AUTOSAR XML (schema 00046)
package /ComponentTypes
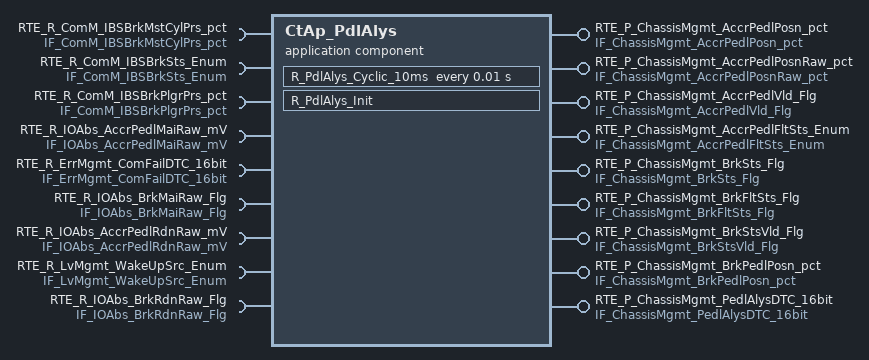
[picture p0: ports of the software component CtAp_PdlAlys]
  application sw component type CtAp_PdlAlys
    9 x provide port:
      RTE_P_ChassisMgmt_AccrPedlPosn_pct: nonqueued-sender-com-spec{data-element=tec_ChassisMgmt_AccrPedlPosn_pct, init-value=0}, provided-interface=IF_ChassisMgmt_AccrPedlPosn_pct
      RTE_P_ChassisMgmt_AccrPedlPosnRaw_pct: nonqueued-sender-com-spec{data-element=tec_ChassisMgmt_AccrPedlPosnRaw_pct, init-value=0}, provided-interface=IF_ChassisMgmt_AccrPedlPosnRaw_pct
      RTE_P_ChassisMgmt_AccrPedlVld_Flg: nonqueued-sender-com-spec{data-element=tec_ChassisMgmt_AccrPedlVld_Flg, init-value=0}, provided-interface=IF_ChassisMgmt_AccrPedlVld_Flg
      RTE_P_ChassisMgmt_AccrPedlFltSts_Enum: nonqueued-sender-com-spec{data-element=tec_ChassisMgmt_AccrPedlFltSts_Enum, init-value=0}, provided-interface=IF_ChassisMgmt_AccrPedlFltSts_Enum
      RTE_P_ChassisMgmt_BrkSts_Flg: nonqueued-sender-com-spec{data-element=tec_ChassisMgmt_BrkSts_Flg, init-value=0}, provided-interface=IF_ChassisMgmt_BrkSts_Flg
      RTE_P_ChassisMgmt_BrkFltSts_Flg: nonqueued-sender-com-spec{data-element=tec_ChassisMgmt_BrkFltSts_Flg, init-value=0}, provided-interface=IF_ChassisMgmt_BrkFltSts_Flg
      RTE_P_ChassisMgmt_BrkStsVld_Flg: nonqueued-sender-com-spec{data-element=tec_ChassisMgmt_BrkStsVld_Flg, init-value=0}, provided-interface=IF_ChassisMgmt_BrkStsVld_Flg
      RTE_P_ChassisMgmt_BrkPedlPosn_pct: nonqueued-sender-com-spec{data-element=tec_ChassisMgmt_BrkPedlPosn_pct, init-value=0}, provided-interface=IF_ChassisMgmt_BrkPedlPosn_pct
      RTE_P_ChassisMgmt_PedlAlysDTC_16bit: nonqueued-sender-com-spec{data-element=tec_ChassisMgmt_PedlAlysDTC_16bit, init-value=0}, provided-interface=IF_ChassisMgmt_PedlAlysDTC_16bit
    9 x require port:
      RTE_R_ComM_IBSBrkMstCylPrs_pct: nonqueued-receiver-com-spec{data-element=tec_ComM_IBSBrkMstCylPrs_pct, filter=data-filter-type=ALWAYS, init-value=0}, required-interface=IF_ComM_IBSBrkMstCylPrs_pct
      RTE_R_ComM_IBSBrkSts_Enum: nonqueued-receiver-com-spec{data-element=tec_ComM_IBSBrkSts_Enum, filter=data-filter-type=ALWAYS, init-value=0}, required-interface=IF_ComM_IBSBrkSts_Enum
      RTE_R_ComM_IBSBrkPlgrPrs_pct: nonqueued-receiver-com-spec{data-element=tec_ComM_IBSBrkPlgrPrs_pct, filter=data-filter-type=ALWAYS, init-value=0}, required-interface=IF_ComM_IBSBrkPlgrPrs_pct
      RTE_R_IOAbs_AccrPedlMaiRaw_mV: nonqueued-receiver-com-spec{data-element=tec_IOAbs_AccrPedlMaiRaw_mV, filter=data-filter-type=ALWAYS, init-value=0}, required-interface=IF_IOAbs_AccrPedlMaiRaw_mV
      RTE_R_ErrMgmt_ComFailDTC_16bit: nonqueued-receiver-com-spec{data-element=tec_ErrMgmt_ComFailDTC_16bit, filter=data-filter-type=ALWAYS, init-value=0}, required-interface=IF_ErrMgmt_ComFailDTC_16bit
      RTE_R_IOAbs_BrkMaiRaw_Flg: nonqueued-receiver-com-spec{data-element=tec_IOAbs_BrkMaiRaw_Flg, filter=data-filter-type=ALWAYS, init-value=0}, required-interface=IF_IOAbs_BrkMaiRaw_Flg
      RTE_R_IOAbs_AccrPedlRdnRaw_mV: nonqueued-receiver-com-spec{data-element=tec_IOAbs_AccrPedlRdnRaw_mV, filter=data-filter-type=ALWAYS, init-value=0}, required-interface=IF_IOAbs_AccrPedlRdnRaw_mV
      RTE_R_LvMgmt_WakeUpSrc_Enum: nonqueued-receiver-com-spec{data-element=tec_LvMgmt_WakeUpSrc_Enum, filter=data-filter-type=ALWAYS, init-value=0}, required-interface=IF_LvMgmt_WakeUpSrc_Enum
      RTE_R_IOAbs_BrkRdnRaw_Flg: nonqueued-receiver-com-spec{data-element=tec_IOAbs_BrkRdnRaw_Flg, filter=data-filter-type=ALWAYS, init-value=0}, required-interface=IF_IOAbs_BrkRdnRaw_Flg
    behavior CtAp_PdlAlys_InternalBehavior
      init event CtAp_PdlAlys_InitEvent: start-on-event=R_PdlAlys_Init
      timing event TMT_R_PdlAlys_Cyclic_10ms: start-on-event=R_PdlAlys_Cyclic_10ms, period=0.01
      runnable R_PdlAlys_Init
      runnable R_PdlAlys_Cyclic_10ms
        data-receive-point-by-arguments:
          9 x access:
            REC_RTE_R_ComM_IBSBrkMstCylPrs_pct_tec_ComM_IBSBrkMstCylPrs_pct: accessed-variable=RTE_R_ComM_IBSBrkMstCylPrs_pct.tec_ComM_IBSBrkMstCylPrs_pct
            REC_RTE_R_ComM_IBSBrkPlgrPrs_pct_tec_ComM_IBSBrkPlgrPrs_pct: accessed-variable=RTE_R_ComM_IBSBrkPlgrPrs_pct.tec_ComM_IBSBrkPlgrPrs_pct
            REC_RTE_R_ComM_IBSBrkSts_Enum_tec_ComM_IBSBrkSts_Enum: accessed-variable=RTE_R_ComM_IBSBrkSts_Enum.tec_ComM_IBSBrkSts_Enum
            REC_RTE_R_ErrMgmt_ComFailDTC_16bit_tec_ErrMgmt_ComFailDTC_16bit: accessed-variable=RTE_R_ErrMgmt_ComFailDTC_16bit.tec_ErrMgmt_ComFailDTC_16bit
            REC_RTE_R_IOAbs_AccrPedlMaiRaw_mV_tec_IOAbs_AccrPedlMaiRaw_mV: accessed-variable=RTE_R_IOAbs_AccrPedlMaiRaw_mV.tec_IOAbs_AccrPedlMaiRaw_mV
            REC_RTE_R_IOAbs_AccrPedlRdnRaw_mV_tec_IOAbs_AccrPedlRdnRaw_mV: accessed-variable=RTE_R_IOAbs_AccrPedlRdnRaw_mV.tec_IOAbs_AccrPedlRdnRaw_mV
            REC_RTE_R_IOAbs_BrkMaiRaw_Flg_tec_IOAbs_BrkMaiRaw_Flg: accessed-variable=RTE_R_IOAbs_BrkMaiRaw_Flg.tec_IOAbs_BrkMaiRaw_Flg
            REC_RTE_R_LvMgmt_WakeUpSrc_Enum_tec_LvMgmt_WakeUpSrc_Enum: accessed-variable=RTE_R_LvMgmt_WakeUpSrc_Enum.tec_LvMgmt_WakeUpSrc_Enum
            REC_RTE_R_IOAbs_BrkRdnRaw_Flg_tec_IOAbs_BrkRdnRaw_Flg: accessed-variable=RTE_R_IOAbs_BrkRdnRaw_Flg.tec_IOAbs_BrkRdnRaw_Flg
        data-send-points:
          9 x access:
            SEND_RTE_P_ChassisMgmt_AccrPedlFltSts_Enum_tec_ChassisMgmt_AccrPedlFltSts_Enum: accessed-variable=RTE_P_ChassisMgmt_AccrPedlFltSts_Enum.tec_ChassisMgmt_AccrPedlFltSts_Enum
            SEND_RTE_P_ChassisMgmt_AccrPedlPosnRaw_pct_tec_ChassisMgmt_AccrPedlPosnRaw_pct: accessed-variable=RTE_P_ChassisMgmt_AccrPedlPosnRaw_pct.tec_ChassisMgmt_AccrPedlPosnRaw_pct
            SEND_RTE_P_ChassisMgmt_AccrPedlPosn_pct_tec_ChassisMgmt_AccrPedlPosn_pct: accessed-variable=RTE_P_ChassisMgmt_AccrPedlPosn_pct.tec_ChassisMgmt_AccrPedlPosn_pct
            SEND_RTE_P_ChassisMgmt_AccrPedlVld_Flg_tec_ChassisMgmt_AccrPedlVld_Flg: accessed-variable=RTE_P_ChassisMgmt_AccrPedlVld_Flg.tec_ChassisMgmt_AccrPedlVld_Flg
            SEND_RTE_P_ChassisMgmt_BrkFltSts_Flg_tec_ChassisMgmt_BrkFltSts_Flg: accessed-variable=RTE_P_ChassisMgmt_BrkFltSts_Flg.tec_ChassisMgmt_BrkFltSts_Flg
            SEND_RTE_P_ChassisMgmt_BrkPedlPosn_pct_tec_ChassisMgmt_BrkPedlPosn_pct: accessed-variable=RTE_P_ChassisMgmt_BrkPedlPosn_pct.tec_ChassisMgmt_BrkPedlPosn_pct
            SEND_RTE_P_ChassisMgmt_BrkStsVld_Flg_tec_ChassisMgmt_BrkStsVld_Flg: accessed-variable=RTE_P_ChassisMgmt_BrkStsVld_Flg.tec_ChassisMgmt_BrkStsVld_Flg
            SEND_RTE_P_ChassisMgmt_BrkSts_Flg_tec_ChassisMgmt_BrkSts_Flg: accessed-variable=RTE_P_ChassisMgmt_BrkSts_Flg.tec_ChassisMgmt_BrkSts_Flg
            SEND_RTE_P_ChassisMgmt_PedlAlysDTC_16bit_tec_ChassisMgmt_PedlAlysDTC_16bit: accessed-variable=RTE_P_ChassisMgmt_PedlAlysDTC_16bit.tec_ChassisMgmt_PedlAlysDTC_16bit
  swc implementation CtAp_PdlAlys_Implementation: behavior=CtAp_PdlAlys_InternalBehavior
    code-descriptors:
      code Default: artifact-descriptors=autosar-engineering-object=category=SWOBJ
